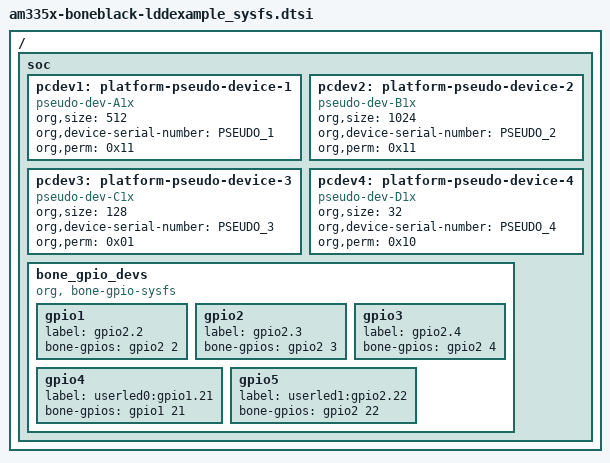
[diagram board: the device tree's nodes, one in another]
/ {
    soc {
        pcdev1: platform-pseudo-device-1 {
            compatible = "pseudo-dev-A1x";
            org,size = <512>;
            org,device-serial-number = "PSEUDO_1";
            org,perm = <0x11>;                      // RDWR
        };

        pcdev2: platform-pseudo-device-2 {
            compatible = "pseudo-dev-B1x";
            org,size = <1024>;
            org,device-serial-number = "PSEUDO_2";
            org,perm = <0x11>;                      // RDWR
        };

        pcdev3: platform-pseudo-device-3 {
            compatible = "pseudo-dev-C1x";
            org,size = <128>;
            org,device-serial-number = "PSEUDO_3";
            org,perm = <0x01>;                      // RDONLY
        };

        pcdev4: platform-pseudo-device-4 {
            compatible = "pseudo-dev-D1x";
            org,size = <32>;
            org,device-serial-number = "PSEUDO_4";
            org,perm = <0x10>;                      // WRONLY
        };

        bone_gpio_devs {
            compatible = "org, bone-gpio-sysfs";
            gpio1 {
                label = "gpio2.2";
                bone-gpios = <&gpio2 2 GPIO_ACTIVE_HIGH>;
            };

            gpio2 {
                label = "gpio2.3";
                bone-gpios = <&gpio2 3 GPIO_ACTIVE_HIGH>;
            };

            gpio3 {
                label = "gpio2.4";
                bone-gpios = <&gpio2 4 GPIO_ACTIVE_HIGH>;
            };

            gpio4 {
                label = "userled0:gpio1.21";
                bone-gpios = <&gpio1 21 GPIO_ACTIVE_HIGH>;
            };

            gpio5 {
                label = "userled1:gpio2.22";
                bone-gpios = <&gpio2 22 GPIO_ACTIVE_HIGH>;
            };
        };
    };
};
